# STM32H7B3 register map
File version: 3.3
CPU: CM7 r0p1, little endian, MPU, FPU, 4 interrupt priority bits
Registers are 32-bit, read-write, reset 0x0 unless marked. A register's access mark holds for its fields unless they carry their own. Offsets are from the block's base; [hi:lo] are bit positions; {n}, {i} and the like mark numbered series.

## DMAMUX2 — DMAMUX
Base 0x58025800
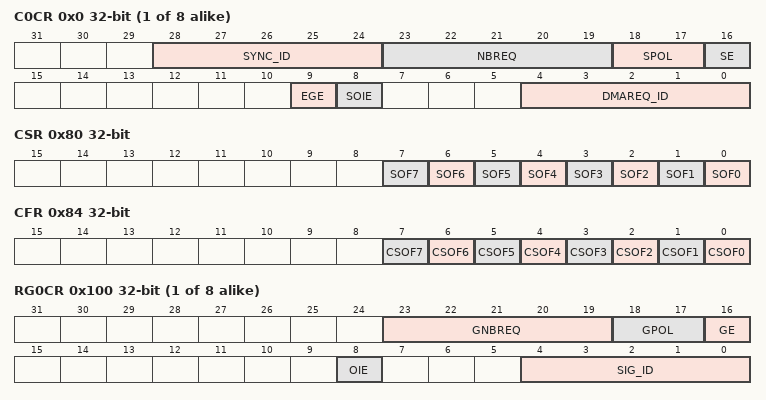
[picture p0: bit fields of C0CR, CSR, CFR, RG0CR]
{0x0+4i} C{i}CR (i=0..7) — DMAMux - DMA request line multiplexer channel x control register
  [28:24] SYNC_ID — Synchronization input selected
  [23:19] NBREQ — Number of DMA requests to forward Defines the number of DMA requests forwarded before output event is generated. In synchronous mode, it also defines the number of DMA requests to forward after a synchronization event, then stop forwarding. The actual number of DMA requests forwarded is NBREQ+1. Note: This field can only be written when both SE and EGE bits are reset.
  [18:17] SPOL — Synchronization event type selector Defines the synchronization event on the selected synchronization input:
  [16] SE — Synchronous operating mode enable/disable
  [9] EGE — Event generation enable/disable
  [8] SOIE — Interrupt enable at synchronization event overrun
  [4:0] DMAREQ_ID — Input DMA request line selected
0x80 CSR ro
  [n] SOF{n} (n=0..7) — Synchronization overrun event flag
0x84 CFR wo
  [n] CSOF{n} (n=0..7) — Clear synchronization overrun event flag Writing 1 in each bit clears the corresponding overrun flag SOFx in the DMAMUX_CSR register.
{0x100+4i} RG{i}CR (i=0..7) — DMAMux - DMA request generator channel x control register
  [23:19] GNBREQ — Number of DMA requests to generate Defines the number of DMA requests generated after a trigger event, then stop generating. The actual number of generated DMA requests is GNBREQ+1. Note: This field can only be written when GE bit is reset.
  [18:17] GPOL — DMA request generator trigger event type selection Defines the trigger event on the selected DMA request trigger input
  [16] GE — DMA request generator channel enable/disable
  [8] OIE — Interrupt enable at trigger event overrun
  [4:0] SIG_ID — DMA request trigger input selected
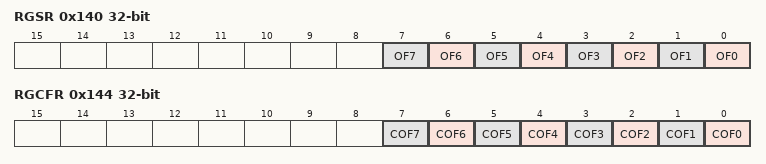
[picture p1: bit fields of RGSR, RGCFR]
0x140 RGSR ro
  [n] OF{n} (n=0..7) — Trigger overrun event flag
0x144 RGCFR ro
  [n] COF{n} (n=0..7) — Clear trigger overrun event flag

## HASH — Hash processor
Base 0x48021400
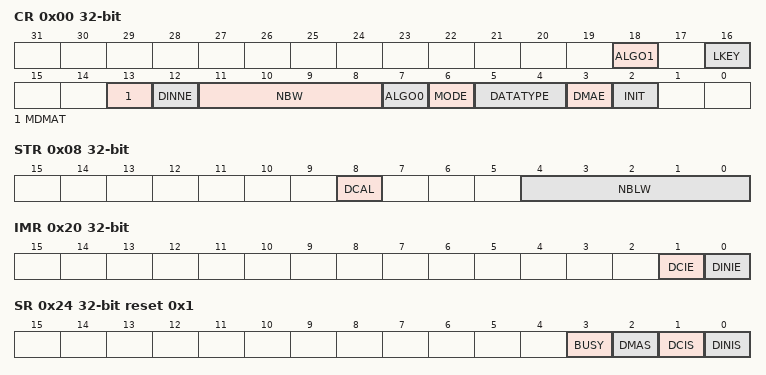
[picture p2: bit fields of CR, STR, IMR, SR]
0x00 CR access per field — control register
  [18] ALGO1 rw — ALGO
  [16] LKEY rw — Long key selection
  [13] MDMAT rw — Multiple DMA Transfers
  [12] DINNE ro — DIN not empty
  [11:8] NBW ro — Number of words already pushed
  [7] ALGO0 rw — Algorithm selection
  [6] MODE rw — Mode selection
  [5:4] DATATYPE rw — Data type selection
  [3] DMAE rw — DMA enable
  [2] INIT wo — Initialize message digest calculation
0x04 DIN — data input register
  [31:0] DATAIN — Data input
0x08 STR access per field — start register
  [8] DCAL wo — Digest calculation
  [4:0] NBLW rw — Number of valid bits in the last word of the message
{0xC+4i} HR{i} ro (i=0..4) — digest registers
  [31:0] H{i}
0x20 IMR — interrupt enable register
  [1] DCIE — Digest calculation completion interrupt enable
  [0] DINIE — Data input interrupt enable
0x24 SR access per field reset 0x1 — status register
  [3] BUSY ro — Busy bit
  [2] DMAS ro — DMA Status
  [1] DCIS rw — Digest calculation completion interrupt status
  [0] DINIS rw — Data input interrupt status
{0xF8+4i} CSR{i} (i=0..53) — context swap registers
0x310 HASH_HR0 ro — HASH digest register
  [31:0] H0
{0x310+4i} HASH_HR{i} ro (i=1..7) — read-only
  [31:0] H{i}

## HRTIM_Master — High Resolution Timer: Master Timers
Base 0x40017400
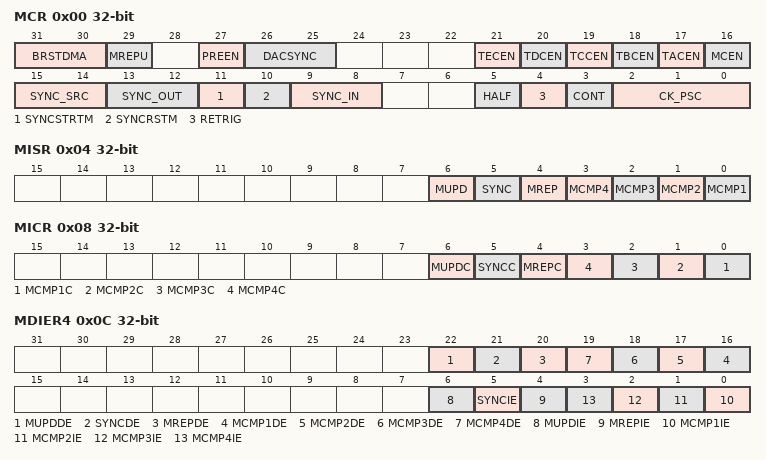
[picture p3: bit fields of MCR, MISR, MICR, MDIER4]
0x00 MCR — Master Timer Control Register
  [31:30] BRSTDMA — Burst DMA Update
  [29] MREPU — Master Timer Repetition update
  [27] PREEN — Preload enable
  [26:25] DACSYNC — AC Synchronization
  [21] TECEN — Timer E counter enable
  [20] TDCEN — Timer D counter enable
  [19] TCCEN — Timer C counter enable
  [18] TBCEN — Timer B counter enable
  [17] TACEN — Timer A counter enable
  [16] MCEN — Master Counter enable
  [15:14] SYNC_SRC — Synchronization source
  [13:12] SYNC_OUT — Synchronization output
  [11] SYNCSTRTM — Synchronization Starts Master
  [10] SYNCRSTM — Synchronization Resets Master
  [9:8] SYNC_IN — ynchronization input
  [5] HALF — Half mode enable
  [4] RETRIG — Master Re-triggerable mode
  [3] CONT — Master Continuous mode
  [2:0] CK_PSC — HRTIM Master Clock prescaler
0x04 MISR ro — Master Timer Interrupt Status Register
  [6] MUPD — Master Update Interrupt Flag
  [5] SYNC — Sync Input Interrupt Flag
  [4] MREP — Master Repetition Interrupt Flag
  [n-1] MCMP{n} (n=1..4) — Master Compare {n} Interrupt Flag
0x08 MICR wo — Master Timer Interrupt Clear Register
  [6] MUPDC — Master update Interrupt flag clear
  [5] SYNCC — Sync Input Interrupt flag clear
  [4] MREPC — Repetition Interrupt flag clear
  [n-1] MCMP{n}C (n=1..4) — Master Compare {n} Interrupt flag clear
0x0C MDIER4
  [22] MUPDDE, [21] SYNCDE, [20] MREPDE, [n+15] MCMP{n}DE (n=1..4), [6] MUPDIE, [5] SYNCIE, [4] MREPIE, [n-1] MCMP{n}IE (n=1..4)
0x10 MCNTR — Master Timer Counter Register
  [15:0] MCNT — Counter value
0x14 MPER reset 0xFFFF — Master Timer Period Register
  [15:0] MPER — Master Timer Period value
0x18 MREP — Master Timer Repetition Register
  [7:0] MREP — Master Timer Repetition counter value
0x1C MCMP1R — Master Timer Compare 1 Register
  [15:0] MCMP1 — Master Timer Compare 1 value
{0x1C+4i} MCMP{i}R (i=2..4) — Master Timer Compare {i} Register
  [15:0] MCMP{i} — Master Timer Compare {i} value
